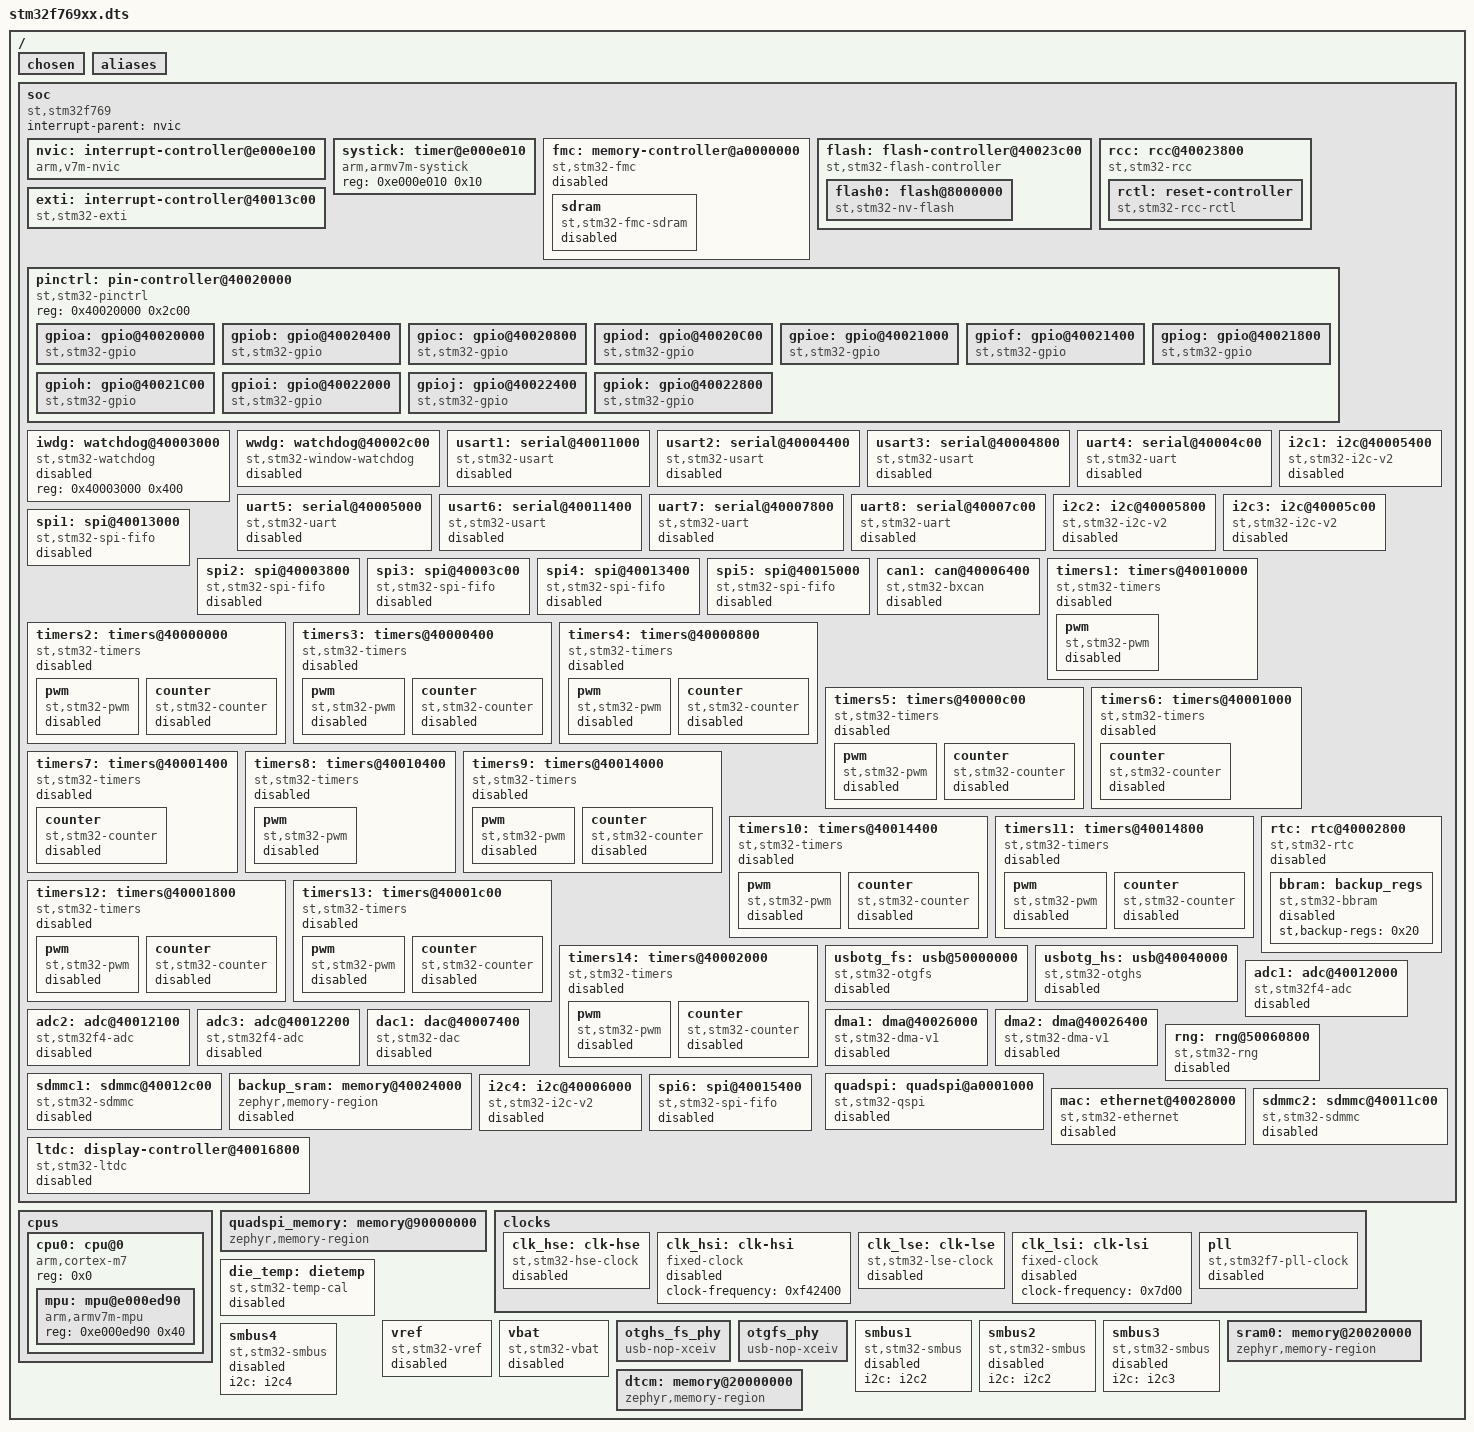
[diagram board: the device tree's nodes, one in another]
/dts-v1/;

/ {
	#address-cells = < 0x1 >;
	#size-cells = < 0x1 >;
	chosen {
		zephyr,entropy = &rng;
		zephyr,flash-controller = &flash;
	};
	aliases {
	};
	soc {
		#address-cells = < 0x1 >;
		#size-cells = < 0x1 >;
		compatible = "st,stm32f769", "st,stm32f7", "simple-bus";
		interrupt-parent = < &nvic >;
		ranges;
		nvic: interrupt-controller@e000e100 {
			#address-cells = < 0x1 >;
			compatible = "arm,v7m-nvic";
			reg = < 0xe000e100 0xc00 >;
			interrupt-controller;
			#interrupt-cells = < 0x2 >;
			arm,num-irq-priority-bits = < 0x4 >;
			phandle = < 0x1 >;
		};
		systick: timer@e000e010 {
			compatible = "arm,armv7m-systick";
			reg = < 0xe000e010 0x10 >;
		};
		fmc: memory-controller@a0000000 {
			compatible = "st,stm32-fmc";
			reg = < 0xa0000000 0x400 >;
			clocks = < &rcc 0x38 0x1 >;
			status = "disabled";
			sdram: sdram {
				compatible = "st,stm32-fmc-sdram";
				#address-cells = < 0x1 >;
				#size-cells = < 0x0 >;
				status = "disabled";
			};
		};
		flash: flash-controller@40023c00 {
			compatible = "st,stm32-flash-controller", "st,stm32f7-flash-controller";
			reg = < 0x40023c00 0x400 >;
			interrupts = < 0x4 0x0 >;
			#address-cells = < 0x1 >;
			#size-cells = < 0x1 >;
			flash0: flash@8000000 {
				compatible = "st,stm32-nv-flash", "soc-nv-flash";
				write-block-size = < 0x1 >;
				max-erase-time = < 0xfa0 >;
				reg = < 0x8000000 0x200000 >;
			};
		};
		rcc: rcc@40023800 {
			compatible = "st,stm32-rcc";
			#clock-cells = < 0x2 >;
			reg = < 0x40023800 0x400 >;
			clock-frequency = < 0x1 >;
			ahb-prescaler = < 0x1 >;
			apb1-prescaler = < 0x1 >;
			apb2-prescaler = < 0x1 >;
			phandle = < 0x2 >;
			rctl: reset-controller {
				compatible = "st,stm32-rcc-rctl";
				#reset-cells = < 0x1 >;
				phandle = < 0x3 >;
			};
		};
		exti: interrupt-controller@40013c00 {
			compatible = "st,stm32-exti";
			interrupt-controller;
			#interrupt-cells = < 0x1 >;
			#address-cells = < 0x1 >;
			reg = < 0x40013c00 0x400 >;
			num-lines = < 0x10 >;
			interrupts = < 0x6 0x0 >, < 0x7 0x0 >, < 0x8 0x0 >, < 0x9 0x0 >, < 0xa 0x0 >, < 0x17 0x0 >, < 0x28 0x0 >;
			interrupt-names = "line0", "line1", "line2", "line3", "line4", "line5-9", "line10-15";
			line-ranges = < 0x0 0x1 >, < 0x1 0x1 >, < 0x2 0x1 >, < 0x3 0x1 >, < 0x4 0x1 >, < 0x5 0x5 >, < 0xa 0x6 >;
		};
		pinctrl: pin-controller@40020000 {
			compatible = "st,stm32-pinctrl";
			#address-cells = < 0x1 >;
			#size-cells = < 0x1 >;
			reg = < 0x40020000 0x2c00 >;
			gpioa: gpio@40020000 {
				compatible = "st,stm32-gpio";
				gpio-controller;
				#gpio-cells = < 0x2 >;
				reg = < 0x40020000 0x400 >;
				clocks = < &rcc 0x30 0x1 >;
			};
			gpiob: gpio@40020400 {
				compatible = "st,stm32-gpio";
				gpio-controller;
				#gpio-cells = < 0x2 >;
				reg = < 0x40020400 0x400 >;
				clocks = < &rcc 0x30 0x2 >;
			};
			gpioc: gpio@40020800 {
				compatible = "st,stm32-gpio";
				gpio-controller;
				#gpio-cells = < 0x2 >;
				reg = < 0x40020800 0x400 >;
				clocks = < &rcc 0x30 0x4 >;
			};
			gpiod: gpio@40020C00 {
				compatible = "st,stm32-gpio";
				gpio-controller;
				#gpio-cells = < 0x2 >;
				reg = < 0x40020c00 0x400 >;
				clocks = < &rcc 0x30 0x8 >;
			};
			gpioe: gpio@40021000 {
				compatible = "st,stm32-gpio";
				gpio-controller;
				#gpio-cells = < 0x2 >;
				reg = < 0x40021000 0x400 >;
				clocks = < &rcc 0x30 0x10 >;
			};
			gpiof: gpio@40021400 {
				compatible = "st,stm32-gpio";
				gpio-controller;
				#gpio-cells = < 0x2 >;
				reg = < 0x40021400 0x400 >;
				clocks = < &rcc 0x30 0x20 >;
			};
			gpiog: gpio@40021800 {
				compatible = "st,stm32-gpio";
				gpio-controller;
				#gpio-cells = < 0x2 >;
				reg = < 0x40021800 0x400 >;
				clocks = < &rcc 0x30 0x40 >;
			};
			gpioh: gpio@40021C00 {
				compatible = "st,stm32-gpio";
				gpio-controller;
				#gpio-cells = < 0x2 >;
				reg = < 0x40021c00 0x400 >;
				clocks = < &rcc 0x30 0x80 >;
			};
			gpioi: gpio@40022000 {
				compatible = "st,stm32-gpio";
				gpio-controller;
				#gpio-cells = < 0x2 >;
				reg = < 0x40022000 0x400 >;
				clocks = < &rcc 0x30 0x100 >;
			};
			gpioj: gpio@40022400 {
				compatible = "st,stm32-gpio";
				gpio-controller;
				#gpio-cells = < 0x2 >;
				reg = < 0x40022400 0x400 >;
				clocks = < &rcc 0x30 0x200 >;
			};
			gpiok: gpio@40022800 {
				compatible = "st,stm32-gpio";
				gpio-controller;
				#gpio-cells = < 0x2 >;
				reg = < 0x40022800 0x400 >;
				clocks = < &rcc 0x30 0x400 >;
			};
		};
		iwdg: watchdog@40003000 {
			compatible = "st,stm32-watchdog";
			reg = < 0x40003000 0x400 >;
			status = "disabled";
		};
		wwdg: watchdog@40002c00 {
			compatible = "st,stm32-window-watchdog";
			reg = < 0x40002c00 0x400 >;
			clocks = < &rcc 0x40 0x800 >;
			interrupts = < 0x0 0x7 >;
			status = "disabled";
		};
		usart1: serial@40011000 {
			compatible = "st,stm32-usart", "st,stm32-uart";
			reg = < 0x40011000 0x400 >;
			clocks = < &rcc 0x44 0x10 >;
			resets = < &rctl 0x484 >;
			interrupts = < 0x25 0x0 >;
			status = "disabled";
		};
		usart2: serial@40004400 {
			compatible = "st,stm32-usart", "st,stm32-uart";
			reg = < 0x40004400 0x400 >;
			clocks = < &rcc 0x40 0x20000 >;
			resets = < &rctl 0x411 >;
			interrupts = < 0x26 0x0 >;
			status = "disabled";
		};
		usart3: serial@40004800 {
			compatible = "st,stm32-usart", "st,stm32-uart";
			reg = < 0x40004800 0x400 >;
			clocks = < &rcc 0x40 0x40000 >;
			resets = < &rctl 0x412 >;
			interrupts = < 0x27 0x0 >;
			status = "disabled";
		};
		uart4: serial@40004c00 {
			compatible = "st,stm32-uart";
			reg = < 0x40004c00 0x400 >;
			clocks = < &rcc 0x40 0x80000 >;
			resets = < &rctl 0x413 >;
			interrupts = < 0x34 0x0 >;
			status = "disabled";
		};
		uart5: serial@40005000 {
			compatible = "st,stm32-uart";
			reg = < 0x40005000 0x400 >;
			clocks = < &rcc 0x40 0x100000 >;
			resets = < &rctl 0x414 >;
			interrupts = < 0x35 0x0 >;
			status = "disabled";
		};
		usart6: serial@40011400 {
			compatible = "st,stm32-usart", "st,stm32-uart";
			reg = < 0x40011400 0x400 >;
			clocks = < &rcc 0x44 0x20 >;
			resets = < &rctl 0x485 >;
			interrupts = < 0x47 0x0 >;
			status = "disabled";
		};
		uart7: serial@40007800 {
			compatible = "st,stm32-uart";
			reg = < 0x40007800 0x400 >;
			clocks = < &rcc 0x40 0x40000000 >;
			resets = < &rctl 0x41e >;
			interrupts = < 0x52 0x0 >;
			status = "disabled";
		};
		uart8: serial@40007c00 {
			compatible = "st,stm32-uart";
			reg = < 0x40007c00 0x400 >;
			clocks = < &rcc 0x40 0x80000000 >;
			resets = < &rctl 0x41f >;
			interrupts = < 0x53 0x0 >;
			status = "disabled";
		};
		i2c1: i2c@40005400 {
			compatible = "st,stm32-i2c-v2";
			clock-frequency = < 0x186a0 >;
			#address-cells = < 0x1 >;
			#size-cells = < 0x0 >;
			reg = < 0x40005400 0x400 >;
			clocks = < &rcc 0x40 0x200000 >;
			interrupts = < 0x1f 0x0 >, < 0x20 0x0 >;
			interrupt-names = "event", "error";
			status = "disabled";
		};
		i2c2: i2c@40005800 {
			compatible = "st,stm32-i2c-v2";
			clock-frequency = < 0x186a0 >;
			#address-cells = < 0x1 >;
			#size-cells = < 0x0 >;
			reg = < 0x40005800 0x400 >;
			clocks = < &rcc 0x40 0x400000 >;
			interrupts = < 0x21 0x0 >, < 0x22 0x0 >;
			interrupt-names = "event", "error";
			status = "disabled";
			phandle = < 0x7 >;
		};
		i2c3: i2c@40005c00 {
			compatible = "st,stm32-i2c-v2";
			clock-frequency = < 0x186a0 >;
			#address-cells = < 0x1 >;
			#size-cells = < 0x0 >;
			reg = < 0x40005c00 0x400 >;
			clocks = < &rcc 0x40 0x800000 >;
			interrupts = < 0x48 0x0 >, < 0x49 0x0 >;
			interrupt-names = "event", "error";
			status = "disabled";
			phandle = < 0x8 >;
		};
		spi1: spi@40013000 {
			compatible = "st,stm32-spi-fifo", "st,stm32-spi";
			#address-cells = < 0x1 >;
			#size-cells = < 0x0 >;
			reg = < 0x40013000 0x400 >;
			clocks = < &rcc 0x44 0x1000 >;
			interrupts = < 0x23 0x5 >;
			status = "disabled";
		};
		spi2: spi@40003800 {
			compatible = "st,stm32-spi-fifo", "st,stm32-spi";
			#address-cells = < 0x1 >;
			#size-cells = < 0x0 >;
			reg = < 0x40003800 0x400 >;
			clocks = < &rcc 0x40 0x4000 >;
			interrupts = < 0x24 0x5 >;
			status = "disabled";
		};
		spi3: spi@40003c00 {
			compatible = "st,stm32-spi-fifo", "st,stm32-spi";
			#address-cells = < 0x1 >;
			#size-cells = < 0x0 >;
			reg = < 0x40003c00 0x400 >;
			clocks = < &rcc 0x40 0x8000 >;
			interrupts = < 0x33 0x5 >;
			status = "disabled";
		};
		spi4: spi@40013400 {
			compatible = "st,stm32-spi-fifo", "st,stm32-spi";
			#address-cells = < 0x1 >;
			#size-cells = < 0x0 >;
			reg = < 0x40013400 0x400 >;
			clocks = < &rcc 0x44 0x2000 >;
			interrupts = < 0x54 0x5 >;
			status = "disabled";
		};
		spi5: spi@40015000 {
			compatible = "st,stm32-spi-fifo", "st,stm32-spi";
			#address-cells = < 0x1 >;
			#size-cells = < 0x0 >;
			reg = < 0x40015000 0x400 >;
			clocks = < &rcc 0x44 0x100000 >;
			interrupts = < 0x55 0x5 >;
			status = "disabled";
		};
		can1: can@40006400 {
			compatible = "st,stm32-bxcan";
			reg = < 0x40006400 0x400 >;
			interrupts = < 0x13 0x0 >, < 0x14 0x0 >, < 0x15 0x0 >, < 0x16 0x0 >;
			interrupt-names = "TX", "RX0", "RX1", "SCE";
			clocks = < &rcc 0x40 0x2000000 >;
			status = "disabled";
		};
		timers1: timers@40010000 {
			compatible = "st,stm32-timers";
			reg = < 0x40010000 0x400 >;
			clocks = < &rcc 0x44 0x1 >;
			resets = < &rctl 0x480 >;
			interrupts = < 0x18 0x0 >, < 0x19 0x0 >, < 0x1a 0x0 >, < 0x1b 0x0 >;
			interrupt-names = "brk", "up", "trgcom", "cc";
			st,prescaler = < 0x0 >;
			status = "disabled";
			pwm {
				compatible = "st,stm32-pwm";
				status = "disabled";
				#pwm-cells = < 0x3 >;
			};
		};
		timers2: timers@40000000 {
			compatible = "st,stm32-timers";
			reg = < 0x40000000 0x400 >;
			clocks = < &rcc 0x40 0x1 >;
			resets = < &rctl 0x400 >;
			interrupts = < 0x1c 0x0 >;
			interrupt-names = "global";
			st,prescaler = < 0x0 >;
			status = "disabled";
			pwm {
				compatible = "st,stm32-pwm";
				status = "disabled";
				#pwm-cells = < 0x3 >;
			};
			counter {
				compatible = "st,stm32-counter";
				status = "disabled";
			};
		};
		timers3: timers@40000400 {
			compatible = "st,stm32-timers";
			reg = < 0x40000400 0x400 >;
			clocks = < &rcc 0x40 0x2 >;
			resets = < &rctl 0x401 >;
			interrupts = < 0x1d 0x0 >;
			interrupt-names = "global";
			st,prescaler = < 0x0 >;
			status = "disabled";
			pwm {
				compatible = "st,stm32-pwm";
				status = "disabled";
				#pwm-cells = < 0x3 >;
			};
			counter {
				compatible = "st,stm32-counter";
				status = "disabled";
			};
		};
		timers4: timers@40000800 {
			compatible = "st,stm32-timers";
			reg = < 0x40000800 0x400 >;
			clocks = < &rcc 0x40 0x4 >;
			resets = < &rctl 0x402 >;
			interrupts = < 0x1e 0x0 >;
			interrupt-names = "global";
			st,prescaler = < 0x0 >;
			status = "disabled";
			pwm {
				compatible = "st,stm32-pwm";
				status = "disabled";
				#pwm-cells = < 0x3 >;
			};
			counter {
				compatible = "st,stm32-counter";
				status = "disabled";
			};
		};
		timers5: timers@40000c00 {
			compatible = "st,stm32-timers";
			reg = < 0x40000c00 0x400 >;
			clocks = < &rcc 0x40 0x8 >;
			resets = < &rctl 0x403 >;
			interrupts = < 0x32 0x0 >;
			interrupt-names = "global";
			st,prescaler = < 0x0 >;
			status = "disabled";
			pwm {
				compatible = "st,stm32-pwm";
				status = "disabled";
				#pwm-cells = < 0x3 >;
			};
			counter {
				compatible = "st,stm32-counter";
				status = "disabled";
			};
		};
		timers6: timers@40001000 {
			compatible = "st,stm32-timers";
			reg = < 0x40001000 0x400 >;
			clocks = < &rcc 0x40 0x10 >;
			resets = < &rctl 0x404 >;
			interrupts = < 0x36 0x0 >;
			interrupt-names = "global";
			st,prescaler = < 0x0 >;
			status = "disabled";
			counter {
				compatible = "st,stm32-counter";
				status = "disabled";
			};
		};
		timers7: timers@40001400 {
			compatible = "st,stm32-timers";
			reg = < 0x40001400 0x400 >;
			clocks = < &rcc 0x40 0x20 >;
			resets = < &rctl 0x405 >;
			interrupts = < 0x37 0x0 >;
			interrupt-names = "global";
			st,prescaler = < 0x0 >;
			status = "disabled";
			counter {
				compatible = "st,stm32-counter";
				status = "disabled";
			};
		};
		timers8: timers@40010400 {
			compatible = "st,stm32-timers";
			reg = < 0x40010400 0x400 >;
			clocks = < &rcc 0x44 0x2 >;
			resets = < &rctl 0x481 >;
			interrupts = < 0x2b 0x0 >, < 0x2c 0x0 >, < 0x2d 0x0 >, < 0x2e 0x0 >;
			interrupt-names = "brk", "up", "trgcom", "cc";
			st,prescaler = < 0x0 >;
			status = "disabled";
			pwm {
				compatible = "st,stm32-pwm";
				status = "disabled";
				#pwm-cells = < 0x3 >;
			};
		};
		timers9: timers@40014000 {
			compatible = "st,stm32-timers";
			reg = < 0x40014000 0x400 >;
			clocks = < &rcc 0x44 0x10000 >;
			resets = < &rctl 0x490 >;
			interrupts = < 0x18 0x0 >;
			interrupt-names = "global";
			st,prescaler = < 0x0 >;
			status = "disabled";
			pwm {
				compatible = "st,stm32-pwm";
				status = "disabled";
				#pwm-cells = < 0x3 >;
			};
			counter {
				compatible = "st,stm32-counter";
				status = "disabled";
			};
		};
		timers10: timers@40014400 {
			compatible = "st,stm32-timers";
			reg = < 0x40014400 0x400 >;
			clocks = < &rcc 0x44 0x20000 >;
			resets = < &rctl 0x491 >;
			interrupts = < 0x19 0x0 >;
			interrupt-names = "global";
			st,prescaler = < 0x0 >;
			status = "disabled";
			pwm {
				compatible = "st,stm32-pwm";
				status = "disabled";
				#pwm-cells = < 0x3 >;
			};
			counter {
				compatible = "st,stm32-counter";
				status = "disabled";
			};
		};
		timers11: timers@40014800 {
			compatible = "st,stm32-timers";
			reg = < 0x40014800 0x400 >;
			clocks = < &rcc 0x44 0x40000 >;
			resets = < &rctl 0x492 >;
			interrupts = < 0x1a 0x0 >;
			interrupt-names = "global";
			st,prescaler = < 0x0 >;
			status = "disabled";
			pwm {
				compatible = "st,stm32-pwm";
				status = "disabled";
				#pwm-cells = < 0x3 >;
			};
			counter {
				compatible = "st,stm32-counter";
				status = "disabled";
			};
		};
		timers12: timers@40001800 {
			compatible = "st,stm32-timers";
			reg = < 0x40001800 0x400 >;
			clocks = < &rcc 0x40 0x40 >;
			resets = < &rctl 0x406 >;
			interrupts = < 0x2b 0x0 >;
			interrupt-names = "global";
			st,prescaler = < 0x0 >;
			status = "disabled";
			pwm {
				compatible = "st,stm32-pwm";
				status = "disabled";
				#pwm-cells = < 0x3 >;
			};
			counter {
				compatible = "st,stm32-counter";
				status = "disabled";
			};
		};
		timers13: timers@40001c00 {
			compatible = "st,stm32-timers";
			reg = < 0x40001c00 0x400 >;
			clocks = < &rcc 0x40 0x80 >;
			resets = < &rctl 0x407 >;
			interrupts = < 0x2c 0x0 >;
			interrupt-names = "global";
			st,prescaler = < 0x0 >;
			status = "disabled";
			pwm {
				compatible = "st,stm32-pwm";
				status = "disabled";
				#pwm-cells = < 0x3 >;
			};
			counter {
				compatible = "st,stm32-counter";
				status = "disabled";
			};
		};
		timers14: timers@40002000 {
			compatible = "st,stm32-timers";
			reg = < 0x40002000 0x400 >;
			clocks = < &rcc 0x40 0x100 >;
			resets = < &rctl 0x408 >;
			interrupts = < 0x2d 0x0 >;
			interrupt-names = "global";
			st,prescaler = < 0x0 >;
			status = "disabled";
			pwm {
				compatible = "st,stm32-pwm";
				status = "disabled";
				#pwm-cells = < 0x3 >;
			};
			counter {
				compatible = "st,stm32-counter";
				status = "disabled";
			};
		};
		usbotg_fs: usb@50000000 {
			compatible = "st,stm32-otgfs";
			reg = < 0x50000000 0x40000 >;
			interrupts = < 0x43 0x0 >;
			interrupt-names = "otgfs";
			num-bidir-endpoints = < 0x6 >;
			ram-size = < 0x500 >;
			maximum-speed = "full-speed";
			phys = < &otgfs_phy >;
			clocks = < &rcc 0x34 0x80 >, < &rcc 0x6 0x3b90 >;
			status = "disabled";
		};
		usbotg_hs: usb@40040000 {
			compatible = "st,stm32-otghs";
			reg = < 0x40040000 0x40000 >;
			interrupts = < 0x4d 0x0 >, < 0x4a 0x0 >, < 0x4b 0x0 >;
			interrupt-names = "otghs", "ep1_out", "ep1_in";
			num-bidir-endpoints = < 0x9 >;
			ram-size = < 0x1000 >;
			maximum-speed = "full-speed";
			clocks = < &rcc 0x30 0x20000000 >;
			phys = < &otghs_fs_phy >;
			status = "disabled";
		};
		rtc: rtc@40002800 {
			compatible = "st,stm32-rtc";
			reg = < 0x40002800 0x300 >;
			interrupts = < 0x29 0x0 >;
			clocks = < &rcc 0x40 0x10000000 >;
			prescaler = < 0x8000 >;
			status = "disabled";
			bbram: backup_regs {
				compatible = "st,stm32-bbram";
				st,backup-regs = < 0x20 >;
				status = "disabled";
			};
		};
		adc1: adc@40012000 {
			compatible = "st,stm32f4-adc", "st,stm32-adc";
			reg = < 0x40012000 0x50 >;
			clocks = < &rcc 0x44 0x100 >;
			interrupts = < 0x12 0x0 >;
			status = "disabled";
			#io-channel-cells = < 0x1 >;
			resolutions = < 0x607804 0x517804 0x427804 0x337804 >;
			sampling-times = < 0x3 0xf 0x1c 0x38 0x54 0x70 0x90 0x1e0 >;
			st,adc-clock-source = < 0x1 >;
			st,adc-sequencer = < 0x1 >;
			phandle = < 0x6 >;
		};
		adc2: adc@40012100 {
			compatible = "st,stm32f4-adc", "st,stm32-adc";
			reg = < 0x40012100 0x50 >;
			clocks = < &rcc 0x44 0x200 >;
			interrupts = < 0x12 0x0 >;
			status = "disabled";
			#io-channel-cells = < 0x1 >;
			resolutions = < 0x607804 0x517804 0x427804 0x337804 >;
			sampling-times = < 0x3 0xf 0x1c 0x38 0x54 0x70 0x90 0x1e0 >;
			st,adc-clock-source = < 0x1 >;
			st,adc-sequencer = < 0x1 >;
		};
		adc3: adc@40012200 {
			compatible = "st,stm32f4-adc", "st,stm32-adc";
			reg = < 0x40012200 0x50 >;
			clocks = < &rcc 0x44 0x400 >;
			interrupts = < 0x12 0x0 >;
			status = "disabled";
			#io-channel-cells = < 0x1 >;
			resolutions = < 0x607804 0x517804 0x427804 0x337804 >;
			sampling-times = < 0x3 0xf 0x1c 0x38 0x54 0x70 0x90 0x1e0 >;
			st,adc-clock-source = < 0x1 >;
			st,adc-sequencer = < 0x1 >;
		};
		dac1: dac@40007400 {
			compatible = "st,stm32-dac";
			reg = < 0x40007400 0x400 >;
			clocks = < &rcc 0x40 0x20000000 >;
			status = "disabled";
			#io-channel-cells = < 0x1 >;
		};
		dma1: dma@40026000 {
			compatible = "st,stm32-dma-v1";
			#dma-cells = < 0x4 >;
			reg = < 0x40026000 0x400 >;
			interrupts = < 0xb 0x0 0xc 0x0 0xd 0x0 0xe 0x0 0xf 0x0 0x10 0x0 0x11 0x0 0x2f 0x0 >;
			clocks = < &rcc 0x30 0x200000 >;
			status = "disabled";
		};
		dma2: dma@40026400 {
			compatible = "st,stm32-dma-v1";
			#dma-cells = < 0x4 >;
			reg = < 0x40026400 0x400 >;
			interrupts = < 0x38 0x0 0x39 0x0 0x3a 0x0 0x3b 0x0 0x3c 0x0 0x44 0x0 0x45 0x0 0x46 0x0 >;
			clocks = < &rcc 0x30 0x400000 >;
			st,mem2mem;
			status = "disabled";
		};
		rng: rng@50060800 {
			compatible = "st,stm32-rng";
			reg = < 0x50060800 0x400 >;
			interrupts = < 0x50 0x0 >;
			clocks = < &rcc 0x34 0x40 >, < &rcc 0x6 0x3b90 >;
			status = "disabled";
		};
		sdmmc1: sdmmc@40012c00 {
			compatible = "st,stm32-sdmmc";
			reg = < 0x40012c00 0x400 >;
			clocks = < &rcc 0x44 0x800 >, < &rcc 0x6 0x3c90 >;
			resets = < &rctl 0x48b >;
			interrupts = < 0x31 0x0 >;
			status = "disabled";
		};
		backup_sram: memory@40024000 {
			compatible = "zephyr,memory-region", "st,stm32-backup-sram";
			reg = < 0x40024000 0x1000 >;
			clocks = < &rcc 0x30 0x40000 >;
			zephyr,memory-region = "BACKUP_SRAM";
			status = "disabled";
		};
		quadspi: quadspi@a0001000 {
			compatible = "st,stm32-qspi";
			#address-cells = < 0x1 >;
			#size-cells = < 0x0 >;
			reg = < 0xa0001000 0x34 >;
			interrupts = < 0x5c 0x0 >;
			clocks = < &rcc 0x38 0x2 >;
			status = "disabled";
		};
		i2c4: i2c@40006000 {
			compatible = "st,stm32-i2c-v2";
			clock-frequency = < 0x186a0 >;
			#address-cells = < 0x1 >;
			#size-cells = < 0x0 >;
			reg = < 0x40006000 0x400 >;
			clocks = < &rcc 0x40 0x1000000 >;
			interrupts = < 0x5f 0x0 >, < 0x60 0x0 >;
			interrupt-names = "event", "error";
			status = "disabled";
			phandle = < 0x9 >;
		};
		spi6: spi@40015400 {
			compatible = "st,stm32-spi-fifo", "st,stm32-spi";
			#address-cells = < 0x1 >;
			#size-cells = < 0x0 >;
			reg = < 0x40015400 0x400 >;
			clocks = < &rcc 0x44 0x200000 >;
			interrupts = < 0x56 0x5 >;
			status = "disabled";
		};
		mac: ethernet@40028000 {
			compatible = "st,stm32-ethernet";
			reg = < 0x40028000 0x8000 >;
			interrupts = < 0x3d 0x0 >;
			clock-names = "stmmaceth", "mac-clk-tx", "mac-clk-rx", "mac-clk-ptp";
			clocks = < &rcc 0x30 0x2000000 >, < &rcc 0x30 0x4000000 >, < &rcc 0x30 0x8000000 >, < &rcc 0x30 0x10000000 >;
			status = "disabled";
		};
		sdmmc2: sdmmc@40011c00 {
			compatible = "st,stm32-sdmmc";
			reg = < 0x40011c00 0x400 >;
			clocks = < &rcc 0x44 0x80 >, < &rcc 0x6 0x3d90 >;
			resets = < &rctl 0x487 >;
			interrupts = < 0x67 0x0 >;
			status = "disabled";
		};
		ltdc: display-controller@40016800 {
			compatible = "st,stm32-ltdc";
			reg = < 0x40016800 0x200 >;
			interrupts = < 0x58 0x0 >, < 0x59 0x0 >;
			interrupt-names = "ltdc", "ltdc_err";
			clocks = < &rcc 0x44 0x4000000 >;
			status = "disabled";
		};
	};
	cpus {
		#address-cells = < 0x1 >;
		#size-cells = < 0x0 >;
		cpu0: cpu@0 {
			device_type = "cpu";
			compatible = "arm,cortex-m7";
			reg = < 0x0 >;
			#address-cells = < 0x1 >;
			#size-cells = < 0x1 >;
			mpu: mpu@e000ed90 {
				compatible = "arm,armv7m-mpu";
				reg = < 0xe000ed90 0x40 >;
			};
		};
	};
	quadspi_memory: memory@90000000 {
		compatible = "zephyr,memory-region", "mmio-sram";
		reg = < 0x90000000 0x10000000 >;
		zephyr,memory-region = "QSPI";
		zephyr,memory-attr = < 0x2000000 >;
	};
	clocks {
		clk_hse: clk-hse {
			#clock-cells = < 0x0 >;
			compatible = "st,stm32-hse-clock";
			status = "disabled";
		};
		clk_hsi: clk-hsi {
			#clock-cells = < 0x0 >;
			compatible = "fixed-clock";
			clock-frequency = < 0xf42400 >;
			status = "disabled";
		};
		clk_lse: clk-lse {
			#clock-cells = < 0x0 >;
			compatible = "st,stm32-lse-clock";
			clock-frequency = < 0x8000 >;
			driving-capability = < 0x0 >;
			status = "disabled";
		};
		clk_lsi: clk-lsi {
			#clock-cells = < 0x0 >;
			compatible = "fixed-clock";
			clock-frequency = < 0x7d00 >;
			status = "disabled";
		};
		pll: pll {
			#clock-cells = < 0x0 >;
			compatible = "st,stm32f7-pll-clock";
			status = "disabled";
		};
	};
	die_temp: dietemp {
		compatible = "st,stm32-temp-cal";
		ts-cal1-addr = < 0x1ff0f44c >;
		ts-cal2-addr = < 0x1ff0f44e >;
		ts-cal1-temp = < 0x1e >;
		ts-cal2-temp = < 0x6e >;
		ts-cal-vrefanalog = < 0xce4 >;
		io-channels = < &adc1 0x12 >;
		status = "disabled";
	};
	vref: vref {
		compatible = "st,stm32-vref";
		vrefint-cal-addr = < 0x1ff0f44a >;
		vrefint-cal-mv = < 0xce4 >;
		io-channels = < &adc1 0x11 >;
		status = "disabled";
	};
	vbat: vbat {
		compatible = "st,stm32-vbat";
		ratio = < 0x4 >;
		io-channels = < &adc1 0x12 >;
		status = "disabled";
	};
	otghs_fs_phy: otghs_fs_phy {
		compatible = "usb-nop-xceiv";
		#phy-cells = < 0x0 >;
		phandle = < 0x5 >;
	};
	otgfs_phy: otgfs_phy {
		compatible = "usb-nop-xceiv";
		#phy-cells = < 0x0 >;
		phandle = < 0x4 >;
	};
	smbus1: smbus1 {
		compatible = "st,stm32-smbus";
		#address-cells = < 0x1 >;
		#size-cells = < 0x0 >;
		i2c = < &i2c2 >;
		status = "disabled";
	};
	smbus2: smbus2 {
		compatible = "st,stm32-smbus";
		#address-cells = < 0x1 >;
		#size-cells = < 0x0 >;
		i2c = < &i2c2 >;
		status = "disabled";
	};
	smbus3: smbus3 {
		compatible = "st,stm32-smbus";
		#address-cells = < 0x1 >;
		#size-cells = < 0x0 >;
		i2c = < &i2c3 >;
		status = "disabled";
	};
	sram0: memory@20020000 {
		compatible = "zephyr,memory-region", "mmio-sram";
		reg = < 0x20020000 0x60000 >;
		zephyr,memory-region = "SRAM0";
	};
	dtcm: memory@20000000 {
		compatible = "zephyr,memory-region", "arm,dtcm";
		reg = < 0x20000000 0x20000 >;
		zephyr,memory-region = "DTCM";
	};
	smbus4: smbus4 {
		compatible = "st,stm32-smbus";
		#address-cells = < 0x1 >;
		#size-cells = < 0x0 >;
		i2c = < &i2c4 >;
		status = "disabled";
	};
};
